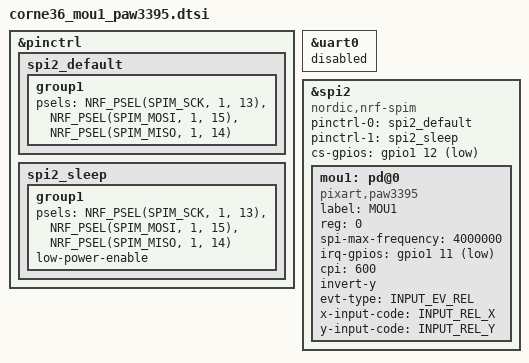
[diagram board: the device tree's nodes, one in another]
/*
 * Copyright (c) 2020 Pete Johanson
 *
 * SPDX-License-Identifier: MIT
 */

&pinctrl {
	spi2_default: spi2_default {
		group1 {
			psels = <NRF_PSEL(SPIM_SCK, 1, 13)>,
							<NRF_PSEL(SPIM_MOSI, 1, 15)>,
							<NRF_PSEL(SPIM_MISO, 1, 14)>;
		};
	};
	spi2_sleep: spi2_sleep {
		group1 {
			psels = <NRF_PSEL(SPIM_SCK, 1, 13)>,
							<NRF_PSEL(SPIM_MOSI, 1, 15)>,
							<NRF_PSEL(SPIM_MISO, 1, 14)>;
			low-power-enable;
		};
	};
};

// release gpio1 11 & 12 from xiao_ble-pinctrl.dtsi
// for &trackball { irq-gpios }
&uart0 {
	status = "disabled";
};

&spi2 {
	compatible = "nordic,nrf-spim";
	status = "disabled"; // <<< disabled in main .dtsi, okay in .overlay
	mou1: pd@0 {
		compatible = "pixart,paw3395";
		status = "disabled";
		label = "MOU1";
		reg = <0>;
		spi-max-frequency = <4000000>;
	};
};

// Config custom gpios
&spi2 {
  status = "okay";
	pinctrl-0 = <&spi2_default>;
	pinctrl-1 = <&spi2_sleep>;
	pinctrl-names = "default", "sleep";
	cs-gpios = <&gpio1 12 GPIO_ACTIVE_LOW>;
};

#include <zephyr/dt-bindings/input/input-event-codes.h>

&mou1 {
  status = "okay";
	irq-gpios = <&gpio1 11 (GPIO_ACTIVE_LOW | GPIO_PULL_UP)>;
	cpi = <600>;
	invert-y;
	evt-type = <INPUT_EV_REL>;
	x-input-code = <INPUT_REL_X>;
	y-input-code = <INPUT_REL_Y>;
};
